# 602 register map
Vendor: bouffalolab; Series: WiFi BT
CPU: 602, little endian
Registers are 32-bit, read-write, reset 0x0 unless marked. A register's access mark holds for its fields unless they carry their own. Offsets are from the block's base; [hi:lo] are bit positions; {n}, {i} and the like mark numbered series.

## rf
Base 0x40001000
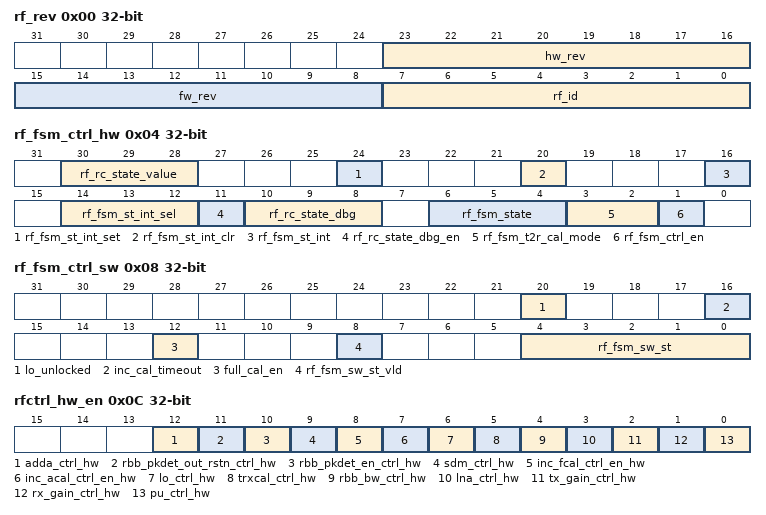
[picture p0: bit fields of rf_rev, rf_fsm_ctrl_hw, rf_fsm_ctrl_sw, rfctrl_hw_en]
0x00 rf_rev — Silicon revision
  [23:16] hw_rev, [15:8] fw_rev, [7:0] rf_id
0x04 rf_fsm_ctrl_hw — Digital Control
  [30:28] rf_rc_state_value, [24] rf_fsm_st_int_set, [20] rf_fsm_st_int_clr, [16] rf_fsm_st_int, [14:12] rf_fsm_st_int_sel, [11] rf_rc_state_dbg_en, [10:8] rf_rc_state_dbg, [6:4] rf_fsm_state, [3:2] rf_fsm_t2r_cal_mode, [1] rf_fsm_ctrl_en
0x08 rf_fsm_ctrl_sw — rfsm status reg
  [20] lo_unlocked, [16] inc_cal_timeout, [12] full_cal_en, [8] rf_fsm_sw_st_vld, [4:0] rf_fsm_sw_st
0x0C rfctrl_hw_en — Control logic switch
  [12] adda_ctrl_hw, [11] rbb_pkdet_out_rstn_ctrl_hw, [10] rbb_pkdet_en_ctrl_hw, [9] sdm_ctrl_hw, [8] inc_fcal_ctrl_en_hw, [7] inc_acal_ctrl_en_hw, [6] lo_ctrl_hw, [5] trxcal_ctrl_hw, [4] rbb_bw_ctrl_hw, [3] lna_ctrl_hw, [2] tx_gain_ctrl_hw, [1] rx_gain_ctrl_hw, [0] pu_ctrl_hw
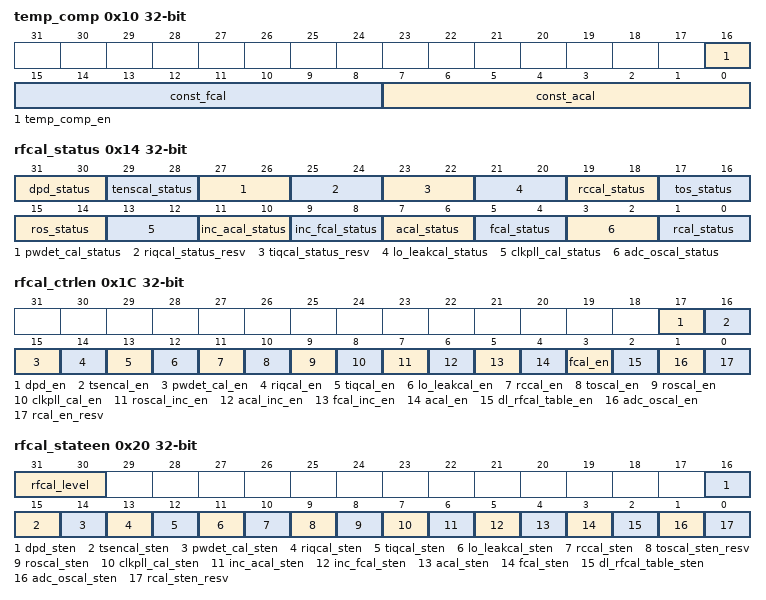
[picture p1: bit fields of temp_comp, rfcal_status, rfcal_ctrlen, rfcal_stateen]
0x10 temp_comp
  [16] temp_comp_en, [15:8] const_fcal, [7:0] const_acal
0x14 rfcal_status
  [31:30] dpd_status, [29:28] tenscal_status, [27:26] pwdet_cal_status, [25:24] riqcal_status_resv, [23:22] tiqcal_status_resv, [21:20] lo_leakcal_status, [19:18] rccal_status, [17:16] tos_status, [15:14] ros_status, [13:12] clkpll_cal_status, [11:10] inc_acal_status, [9:8] inc_fcal_status, [7:6] acal_status, [5:4] fcal_status, [3:2] adc_oscal_status, [1:0] rcal_status
0x18 rfcal_status2
  [1:0] dl_rfcal_table_status
0x1C rfcal_ctrlen — Calibration mode register
  [17] dpd_en, [16] tsencal_en, [15] pwdet_cal_en, [14] riqcal_en, [13] tiqcal_en, [12] lo_leakcal_en, [11] rccal_en, [10] toscal_en, [9] roscal_en, [8] clkpll_cal_en, [7] roscal_inc_en, [6] acal_inc_en, [5] fcal_inc_en, [4] acal_en, [3] fcal_en, [2] dl_rfcal_table_en, [1] adc_oscal_en, [0] rcal_en_resv
0x20 rfcal_stateen — rf calibration state enabl in full cal list
  [31:30] rfcal_level, [16] dpd_sten, [15] tsencal_sten, [14] pwdet_cal_sten, [13] riqcal_sten, [12] tiqcal_sten, [11] lo_leakcal_sten, [10] rccal_sten, [9] toscal_sten_resv, [8] roscal_sten, [7] clkpll_cal_sten, [6] inc_acal_sten, [5] inc_fcal_sten, [4] acal_sten, [3] fcal_sten, [2] dl_rfcal_table_sten, [1] adc_oscal_sten, [0] rcal_sten_resv
0x24 saradc_resv — SARADC Control Registers
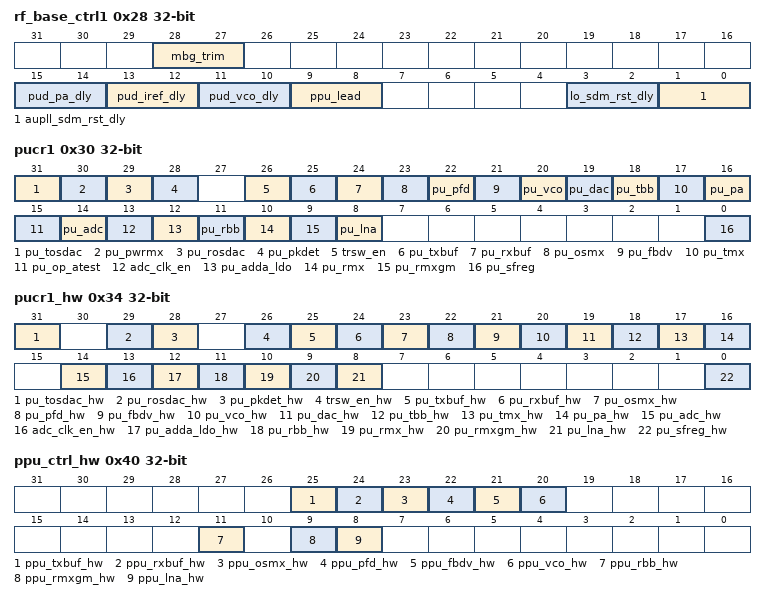
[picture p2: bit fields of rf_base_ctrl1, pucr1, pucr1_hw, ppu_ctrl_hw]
0x28 rf_base_ctrl1 — ZRF Control register 0
  [28:27] mbg_trim, [15:14] pud_pa_dly, [13:12] pud_iref_dly, [11:10] pud_vco_dly, [9:8] ppu_lead, [3:2] lo_sdm_rst_dly, [1:0] aupll_sdm_rst_dly
0x2C rf_base_ctrl2 — ZRF Control register 0
0x30 pucr1
  [31] pu_tosdac, [30] pu_pwrmx, [29] pu_rosdac, [28] pu_pkdet, [26] trsw_en, [25] pu_txbuf, [24] pu_rxbuf, [23] pu_osmx, [22] pu_pfd, [21] pu_fbdv, [20] pu_vco, [19] pu_dac, [18] pu_tbb, [17] pu_tmx, [16] pu_pa, [15] pu_op_atest, [14] pu_adc, [13] adc_clk_en, [12] pu_adda_ldo, [11] pu_rbb, [10] pu_rmx, [9] pu_rmxgm, [8] pu_lna, [0] pu_sfreg
0x34 pucr1_hw — read only from hardware logic
  [31] pu_tosdac_hw, [29] pu_rosdac_hw, [28] pu_pkdet_hw, [26] trsw_en_hw, [25] pu_txbuf_hw, [24] pu_rxbuf_hw, [23] pu_osmx_hw, [22] pu_pfd_hw, [21] pu_fbdv_hw, [20] pu_vco_hw, [19] pu_dac_hw, [18] pu_tbb_hw, [17] pu_tmx_hw, [16] pu_pa_hw, [14] pu_adc_hw, [13] adc_clk_en_hw, [12] pu_adda_ldo_hw, [11] pu_rbb_hw, [10] pu_rmx_hw, [9] pu_rmxgm_hw, [8] pu_lna_hw, [0] pu_sfreg_hw
0x38 pucr2
0x3C pucr2_hw
0x40 ppu_ctrl_hw
  [25] ppu_txbuf_hw, [24] ppu_rxbuf_hw, [23] ppu_osmx_hw, [22] ppu_pfd_hw, [21] ppu_fbdv_hw, [20] ppu_vco_hw, [11] ppu_rbb_hw, [9] ppu_rmxgm_hw, [8] ppu_lna_hw
0x44 pud_ctrl_hw
  [20] pud_vco_hw
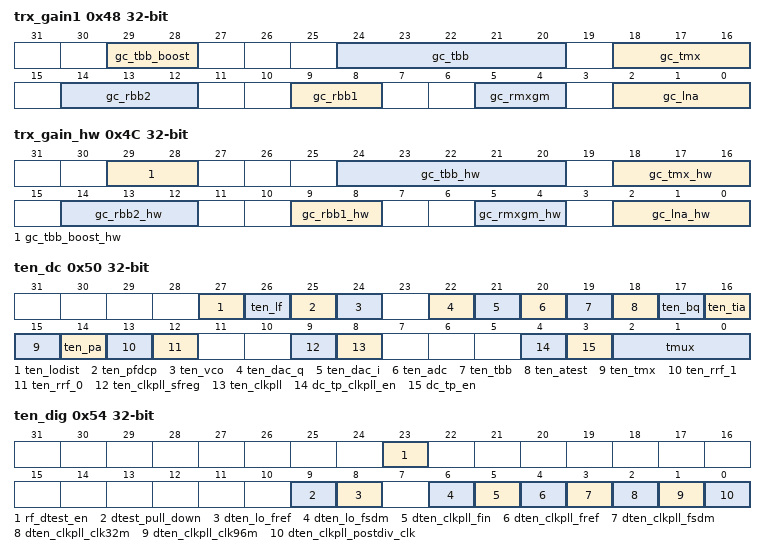
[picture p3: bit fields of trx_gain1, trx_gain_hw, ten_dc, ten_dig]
0x48 trx_gain1 — gain control1
  [29:28] gc_tbb_boost, [24:20] gc_tbb, [18:16] gc_tmx, [14:12] gc_rbb2, [9:8] gc_rbb1, [5:4] gc_rmxgm, [2:0] gc_lna
0x4C trx_gain_hw — trx gain hardware readback
  [29:28] gc_tbb_boost_hw, [24:20] gc_tbb_hw, [18:16] gc_tmx_hw, [14:12] gc_rbb2_hw, [9:8] gc_rbb1_hw, [5:4] gc_rmxgm_hw, [2:0] gc_lna_hw
0x50 ten_dc — dc test register
  [27] ten_lodist, [26] ten_lf, [25] ten_pfdcp, [24] ten_vco, [22] ten_dac_q, [21] ten_dac_i, [20] ten_adc, [19] ten_tbb, [18] ten_atest, [17] ten_bq, [16] ten_tia, [15] ten_tmx, [14] ten_pa, [13] ten_rrf_1, [12] ten_rrf_0, [9] ten_clkpll_sfreg, [8] ten_clkpll, [4] dc_tp_clkpll_en, [3] dc_tp_en, [2:0] tmux
0x54 ten_dig — digital test register
  [23] rf_dtest_en, [9] dtest_pull_down, [8] dten_lo_fref, [6] dten_lo_fsdm, [5] dten_clkpll_fin, [4] dten_clkpll_fref, [3] dten_clkpll_fsdm, [2] dten_clkpll_clk32m, [1] dten_clkpll_clk96m, [0] dten_clkpll_postdiv_clk
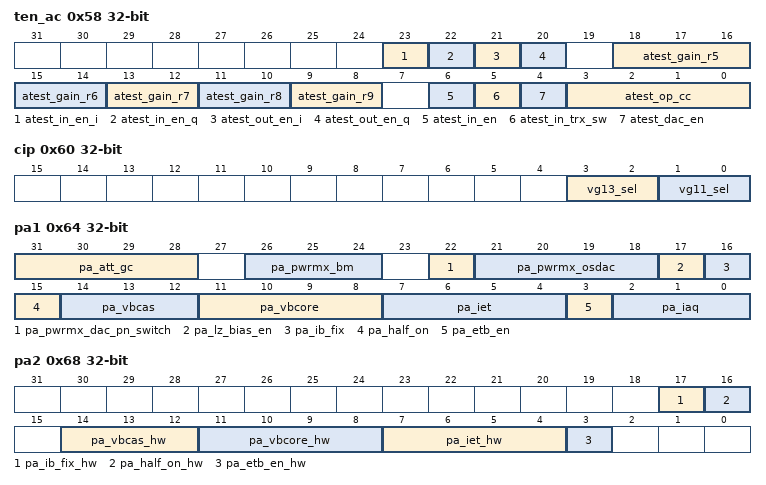
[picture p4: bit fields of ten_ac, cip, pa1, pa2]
0x58 ten_ac — ac test register
  [23] atest_in_en_i, [22] atest_in_en_q, [21] atest_out_en_i, [20] atest_out_en_q, [18:16] atest_gain_r5, [27-2n:26-2n] atest_gain_r{n} (n=6..9), [6] atest_in_en, [5] atest_in_trx_sw, [4] atest_dac_en, [3:0] atest_op_cc
0x5C pmip_mv2aon
0x60 cip — RX normal bias mode registers
  [3:2] vg13_sel, [1:0] vg11_sel
0x64 pa1
  [31:28] pa_att_gc, [26:24] pa_pwrmx_bm, [22] pa_pwrmx_dac_pn_switch, [21:18] pa_pwrmx_osdac, [17] pa_lz_bias_en, [16] pa_ib_fix, [15] pa_half_on, [14:12] pa_vbcas, [11:8] pa_vbcore, [7:4] pa_iet, [3] pa_etb_en, [2:0] pa_iaq
0x68 pa2 — RX normal bias mode registers
  [17] pa_ib_fix_hw, [16] pa_half_on_hw, [14:12] pa_vbcas_hw, [11:8] pa_vbcore_hw, [7:4] pa_iet_hw, [3] pa_etb_en_hw
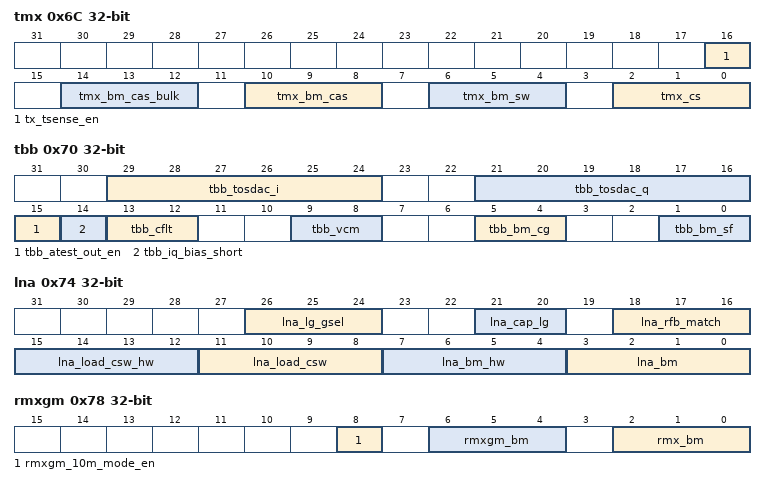
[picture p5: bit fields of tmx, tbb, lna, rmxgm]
0x6C tmx
  [16] tx_tsense_en, [14:12] tmx_bm_cas_bulk, [10:8] tmx_bm_cas, [6:4] tmx_bm_sw, [2:0] tmx_cs
0x70 tbb
  [29:24] tbb_tosdac_i, [21:16] tbb_tosdac_q, [15] tbb_atest_out_en, [14] tbb_iq_bias_short, [13:12] tbb_cflt, [9:8] tbb_vcm, [5:4] tbb_bm_cg, [1:0] tbb_bm_sf
0x74 lna
  [26:24] lna_lg_gsel, [21:20] lna_cap_lg, [18:16] lna_rfb_match, [15:12] lna_load_csw_hw, [11:8] lna_load_csw, [7:4] lna_bm_hw, [3:0] lna_bm
0x78 rmxgm
  [8] rmxgm_10m_mode_en, [6:4] rmxgm_bm, [2:0] rmx_bm
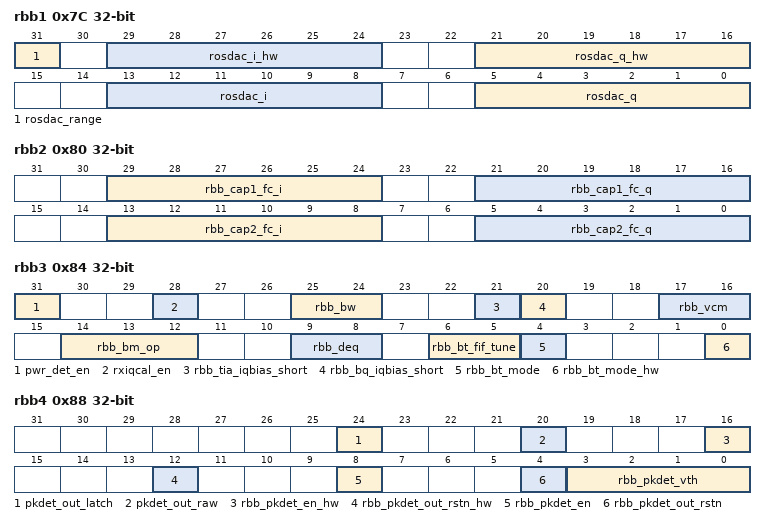
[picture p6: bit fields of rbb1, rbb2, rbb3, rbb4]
0x7C rbb1
  [31] rosdac_range, [29:24] rosdac_i_hw, [21:16] rosdac_q_hw, [13:8] rosdac_i, [5:0] rosdac_q
0x80 rbb2
  [29:24] rbb_cap1_fc_i, [21:16] rbb_cap1_fc_q, [13:8] rbb_cap2_fc_i, [5:0] rbb_cap2_fc_q
0x84 rbb3
  [31] pwr_det_en, [28] rxiqcal_en, [25:24] rbb_bw, [21] rbb_tia_iqbias_short, [20] rbb_bq_iqbias_short, [17:16] rbb_vcm, [14:12] rbb_bm_op, [9:8] rbb_deq, [6:5] rbb_bt_fif_tune, [4] rbb_bt_mode, [0] rbb_bt_mode_hw
0x88 rbb4
  [24] pkdet_out_latch, [20] pkdet_out_raw, [16] rbb_pkdet_en_hw, [12] rbb_pkdet_out_rstn_hw, [8] rbb_pkdet_en, [4] rbb_pkdet_out_rstn, [3:0] rbb_pkdet_vth
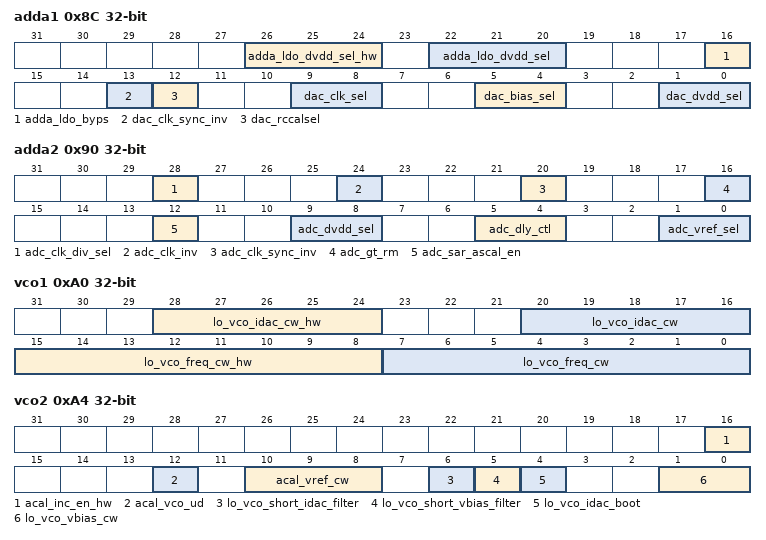
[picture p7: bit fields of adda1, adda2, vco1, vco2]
0x8C adda1
  [26:24] adda_ldo_dvdd_sel_hw, [22:20] adda_ldo_dvdd_sel, [16] adda_ldo_byps, [13] dac_clk_sync_inv, [12] dac_rccalsel, [9:8] dac_clk_sel, [5:4] dac_bias_sel, [1:0] dac_dvdd_sel
0x90 adda2
  [28] adc_clk_div_sel, [24] adc_clk_inv, [20] adc_clk_sync_inv, [16] adc_gt_rm, [12] adc_sar_ascal_en, [9:8] adc_dvdd_sel, [5:4] adc_dly_ctl, [1:0] adc_vref_sel
0xA0 vco1
  [28:24] lo_vco_idac_cw_hw, [20:16] lo_vco_idac_cw, [15:8] lo_vco_freq_cw_hw, [7:0] lo_vco_freq_cw
0xA4 vco2
  [16] acal_inc_en_hw, [12] acal_vco_ud, [10:8] acal_vref_cw, [6] lo_vco_short_idac_filter, [5] lo_vco_short_vbias_filter, [4] lo_vco_idac_boot, [1:0] lo_vco_vbias_cw
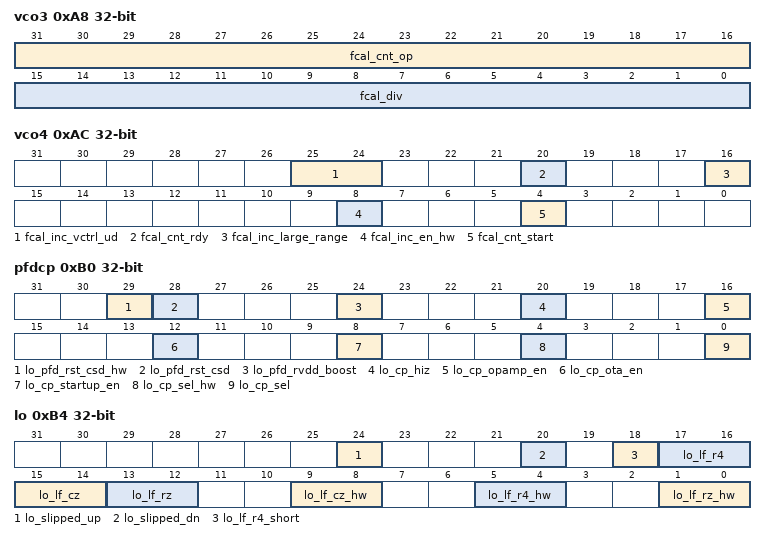
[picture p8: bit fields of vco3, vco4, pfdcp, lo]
0xA8 vco3
  [31:16] fcal_cnt_op, [15:0] fcal_div
0xAC vco4
  [25:24] fcal_inc_vctrl_ud, [20] fcal_cnt_rdy, [16] fcal_inc_large_range, [8] fcal_inc_en_hw, [4] fcal_cnt_start
0xB0 pfdcp
  [29] lo_pfd_rst_csd_hw, [28] lo_pfd_rst_csd, [24] lo_pfd_rvdd_boost, [20] lo_cp_hiz, [16] lo_cp_opamp_en, [12] lo_cp_ota_en, [8] lo_cp_startup_en, [4] lo_cp_sel_hw, [0] lo_cp_sel
0xB4 lo
  [24] lo_slipped_up, [20] lo_slipped_dn, [18] lo_lf_r4_short, [17:16] lo_lf_r4, [15:14] lo_lf_cz, [13:12] lo_lf_rz, [9:8] lo_lf_cz_hw, [5:4] lo_lf_r4_hw, [1:0] lo_lf_rz_hw
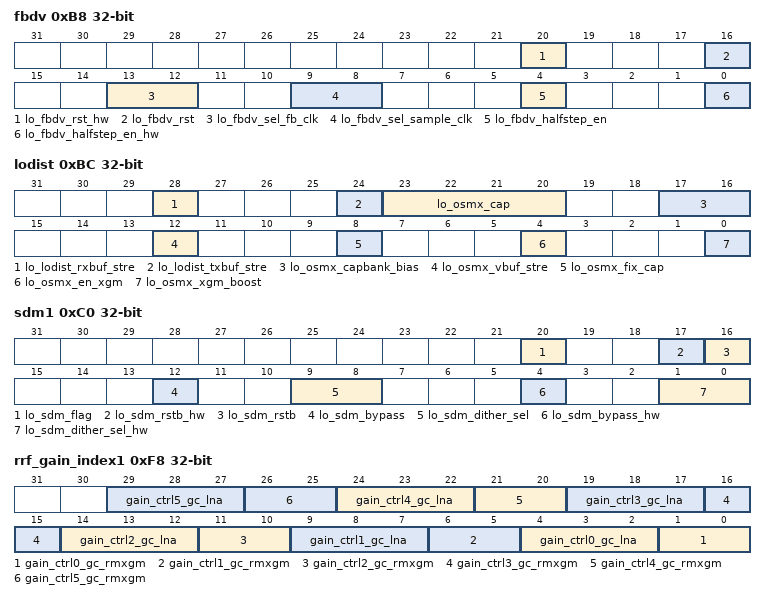
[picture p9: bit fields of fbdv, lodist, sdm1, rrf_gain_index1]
0xB8 fbdv
  [20] lo_fbdv_rst_hw, [16] lo_fbdv_rst, [13:12] lo_fbdv_sel_fb_clk, [9:8] lo_fbdv_sel_sample_clk, [4] lo_fbdv_halfstep_en, [0] lo_fbdv_halfstep_en_hw
0xBC lodist
  [28] lo_lodist_rxbuf_stre, [24] lo_lodist_txbuf_stre, [23:20] lo_osmx_cap, [17:16] lo_osmx_capbank_bias, [12] lo_osmx_vbuf_stre, [8] lo_osmx_fix_cap, [4] lo_osmx_en_xgm, [0] lo_osmx_xgm_boost
0xC0 sdm1
  [20] lo_sdm_flag, [17] lo_sdm_rstb_hw, [16] lo_sdm_rstb, [12] lo_sdm_bypass, [9:8] lo_sdm_dither_sel, [4] lo_sdm_bypass_hw, [1:0] lo_sdm_dither_sel_hw
0xC4 sdm2
  [29:0] lo_sdmin
0xC8 sdm3
  [29:0] lo_sdmin_hw
{0xEC+4i} rf_resv_reg_{i} (i=0..2)
  [31:0] rf_reserved{i}
0xF8 rrf_gain_index1
  [5n+4:5n+2] gain_ctrl{n}_gc_lna (n=0..5), [5n+1:5n] gain_ctrl{n}_gc_rmxgm (n=0..5)
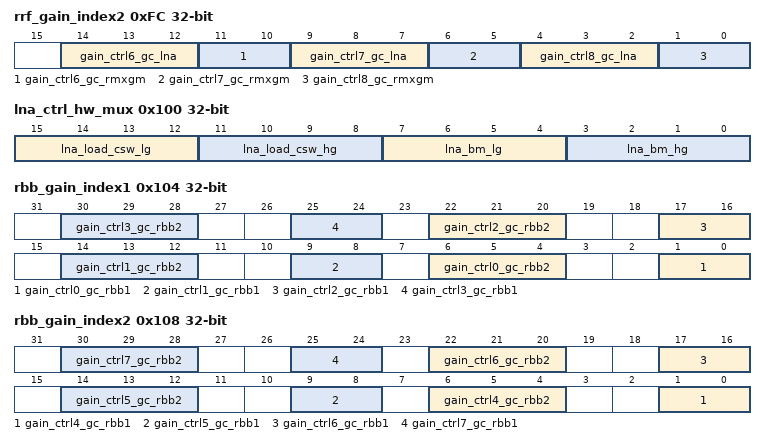
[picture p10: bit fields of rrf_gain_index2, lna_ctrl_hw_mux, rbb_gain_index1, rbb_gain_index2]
0xFC rrf_gain_index2
  [14:12] gain_ctrl6_gc_lna, [11:10] gain_ctrl6_gc_rmxgm, [9:7] gain_ctrl7_gc_lna, [6:5] gain_ctrl7_gc_rmxgm, [4:2] gain_ctrl8_gc_lna, [1:0] gain_ctrl8_gc_rmxgm
0x100 lna_ctrl_hw_mux
  [15:12] lna_load_csw_lg, [11:8] lna_load_csw_hg, [7:4] lna_bm_lg, [3:0] lna_bm_hg
0x104 rbb_gain_index1
  [8n+6:8n+4] gain_ctrl{n}_gc_rbb2 (n=0..3), [8n+1:8n] gain_ctrl{n}_gc_rbb1 (n=0..3)
0x108 rbb_gain_index2
  [8n-26:8n-28] gain_ctrl{n}_gc_rbb2 (n=4..7), [8n-31:8n-32] gain_ctrl{n}_gc_rbb1 (n=4..7)
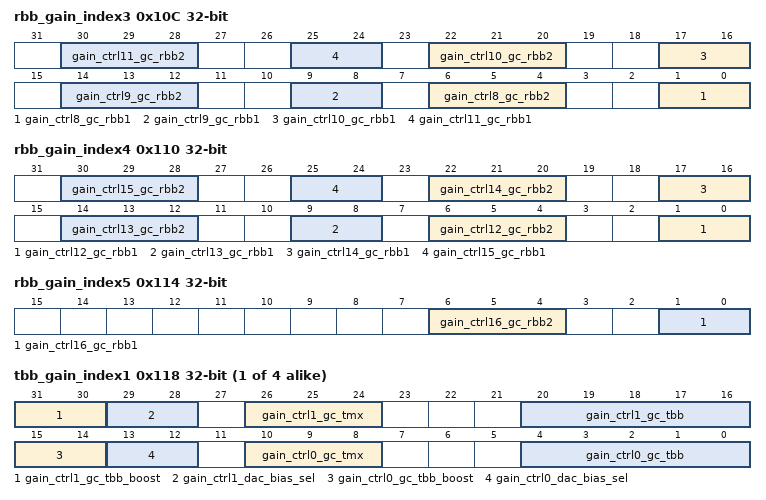
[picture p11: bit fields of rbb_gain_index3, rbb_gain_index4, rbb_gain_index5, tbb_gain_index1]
0x10C rbb_gain_index3
  [8n-58:8n-60] gain_ctrl{n}_gc_rbb2 (n=8..11), [8n-63:8n-64] gain_ctrl{n}_gc_rbb1 (n=8..11)
0x110 rbb_gain_index4
  [8n-90:8n-92] gain_ctrl{n}_gc_rbb2 (n=12..15), [8n-95:8n-96] gain_ctrl{n}_gc_rbb1 (n=12..15)
0x114 rbb_gain_index5
  [6:4] gain_ctrl16_gc_rbb2, [1:0] gain_ctrl16_gc_rbb1
{0x114+4i} tbb_gain_index{i} (i=1..4)
  [31:30] gain_ctrl{2i-1}_gc_tbb_boost, [29:28] gain_ctrl{2i-1}_dac_bias_sel, [26:24] gain_ctrl{2i-1}_gc_tmx, [20:16] gain_ctrl{2i-1}_gc_tbb, [15:14] gain_ctrl{2i-2}_gc_tbb_boost, [13:12] gain_ctrl{2i-2}_dac_bias_sel, [10:8] gain_ctrl{2i-2}_gc_tmx, [4:0] gain_ctrl{2i-2}_gc_tbb
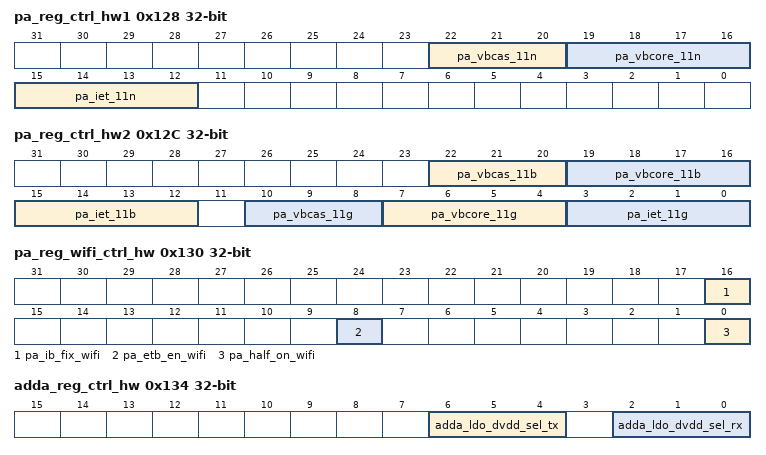
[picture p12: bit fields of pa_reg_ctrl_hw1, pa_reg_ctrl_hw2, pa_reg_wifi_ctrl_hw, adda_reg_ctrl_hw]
0x128 pa_reg_ctrl_hw1
  [22:20] pa_vbcas_11n, [19:16] pa_vbcore_11n, [15:12] pa_iet_11n
0x12C pa_reg_ctrl_hw2
  [22:20] pa_vbcas_11b, [19:16] pa_vbcore_11b, [15:12] pa_iet_11b, [10:8] pa_vbcas_11g, [7:4] pa_vbcore_11g, [3:0] pa_iet_11g
0x130 pa_reg_wifi_ctrl_hw
  [16] pa_ib_fix_wifi, [8] pa_etb_en_wifi, [0] pa_half_on_wifi
0x134 adda_reg_ctrl_hw
  [6:4] adda_ldo_dvdd_sel_tx, [2:0] adda_ldo_dvdd_sel_rx
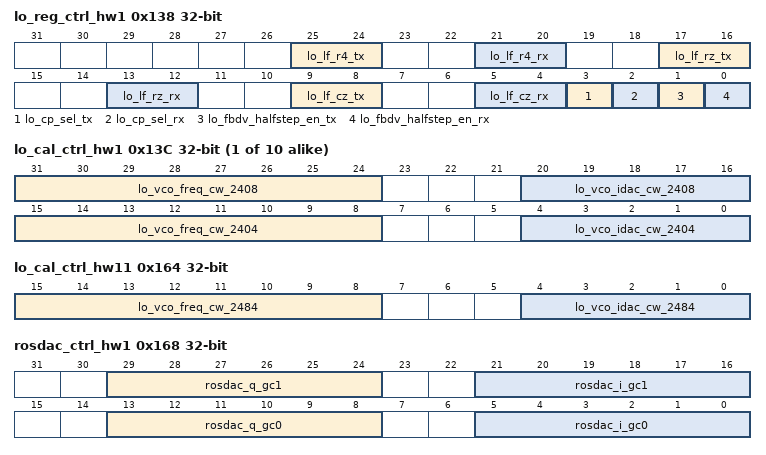
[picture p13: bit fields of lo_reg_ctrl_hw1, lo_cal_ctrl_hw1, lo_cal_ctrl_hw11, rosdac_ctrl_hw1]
0x138 lo_reg_ctrl_hw1
  [25:24] lo_lf_r4_tx, [21:20] lo_lf_r4_rx, [17:16] lo_lf_rz_tx, [13:12] lo_lf_rz_rx, [9:8] lo_lf_cz_tx, [5:4] lo_lf_cz_rx, [3] lo_cp_sel_tx, [2] lo_cp_sel_rx, [1] lo_fbdv_halfstep_en_tx, [0] lo_fbdv_halfstep_en_rx
{0x138+4i} lo_cal_ctrl_hw{i} (i=1..10)
  [31:24] lo_vco_freq_cw_{8i+2400}, [20:16] lo_vco_idac_cw_{8i+2400}, [15:8] lo_vco_freq_cw_{8i+2396}, [4:0] lo_vco_idac_cw_{8i+2396}
0x164 lo_cal_ctrl_hw11
  [15:8] lo_vco_freq_cw_2484, [4:0] lo_vco_idac_cw_2484
0x168 rosdac_ctrl_hw1
  [29:24] rosdac_q_gc1, [21:16] rosdac_i_gc1, [13:8] rosdac_q_gc0, [5:0] rosdac_i_gc0
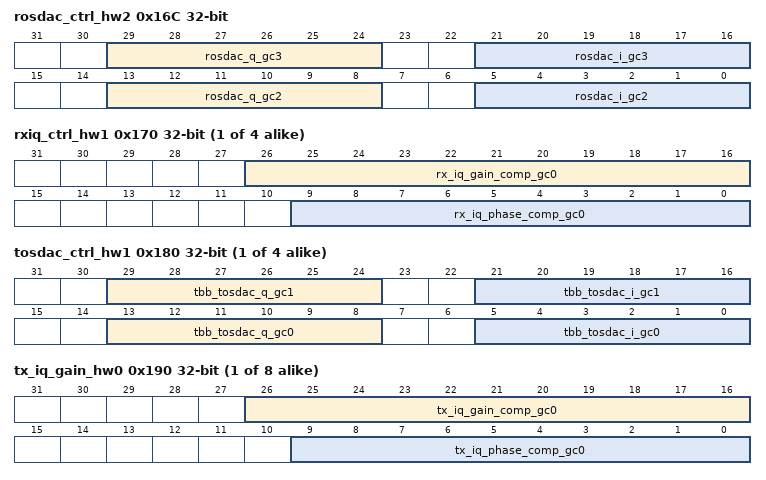
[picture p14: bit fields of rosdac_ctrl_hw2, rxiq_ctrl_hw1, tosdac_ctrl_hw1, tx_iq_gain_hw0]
0x16C rosdac_ctrl_hw2
  [29:24] rosdac_q_gc3, [21:16] rosdac_i_gc3, [13:8] rosdac_q_gc2, [5:0] rosdac_i_gc2
{0x16C+4i} rxiq_ctrl_hw{i} (i=1..4)
  [26:16] rx_iq_gain_comp_gc{i-1}, [9:0] rx_iq_phase_comp_gc{i-1}
{0x17C+4i} tosdac_ctrl_hw{i} (i=1..4)
  [29:24] tbb_tosdac_q_gc{2i-1}, [21:16] tbb_tosdac_i_gc{2i-1}, [13:8] tbb_tosdac_q_gc{2i-2}, [5:0] tbb_tosdac_i_gc{2i-2}
{0x190+4i} tx_iq_gain_hw{i} (i=0..7)
  [26:16] tx_iq_gain_comp_gc{i}, [9:0] tx_iq_phase_comp_gc{i}
0x1B0 lo_sdm_ctrl_hw1
  [27:26] lo_sdm_dither_sel_wlan_2484, [25:24] lo_sdm_dither_sel_wlan_2472, [23:22] lo_sdm_dither_sel_wlan_2467, [21:20] lo_sdm_dither_sel_wlan_2462, [19:18] lo_sdm_dither_sel_wlan_2457, [17:16] lo_sdm_dither_sel_wlan_2452, [15:14] lo_sdm_dither_sel_wlan_2447, [13:12] lo_sdm_dither_sel_wlan_2442, [11:10] lo_sdm_dither_sel_wlan_2437, [9:8] lo_sdm_dither_sel_wlan_2432, [7:6] lo_sdm_dither_sel_wlan_2427, [5:4] lo_sdm_dither_sel_wlan_2422, [3:2] lo_sdm_dither_sel_wlan_2417, [1:0] lo_sdm_dither_sel_wlan_2412
0x1B4 lo_sdm_ctrl_hw2
  [31:30] lo_sdm_dither_sel_ble_2432, [29:28] lo_sdm_dither_sel_ble_2430, [27:26] lo_sdm_dither_sel_ble_2428, [25:24] lo_sdm_dither_sel_ble_2426, [23:22] lo_sdm_dither_sel_ble_2424, [21:20] lo_sdm_dither_sel_ble_2422, [19:18] lo_sdm_dither_sel_ble_2420, [17:16] lo_sdm_dither_sel_ble_2418, [15:14] lo_sdm_dither_sel_ble_2416, [13:12] lo_sdm_dither_sel_ble_2414, [11:10] lo_sdm_dither_sel_ble_2412, [9:8] lo_sdm_dither_sel_ble_2410, [7:6] lo_sdm_dither_sel_ble_2408, [5:4] lo_sdm_dither_sel_ble_2406, [3:2] lo_sdm_dither_sel_ble_2404, [1:0] lo_sdm_dither_sel_ble_2402
0x1B8 lo_sdm_ctrl_hw3
  [31:30] lo_sdm_dither_sel_ble_2464, [29:28] lo_sdm_dither_sel_ble_2462, [27:26] lo_sdm_dither_sel_ble_2460, [25:24] lo_sdm_dither_sel_ble_2458, [23:22] lo_sdm_dither_sel_ble_2456, [21:20] lo_sdm_dither_sel_ble_2454, [19:18] lo_sdm_dither_sel_ble_2452, [17:16] lo_sdm_dither_sel_ble_2450, [15:14] lo_sdm_dither_sel_ble_2448, [13:12] lo_sdm_dither_sel_ble_2446, [11:10] lo_sdm_dither_sel_ble_2444, [9:8] lo_sdm_dither_sel_ble_2442, [7:6] lo_sdm_dither_sel_ble_2440, [5:4] lo_sdm_dither_sel_ble_2438, [3:2] lo_sdm_dither_sel_ble_2436, [1:0] lo_sdm_dither_sel_ble_2434
0x1BC lo_sdm_ctrl_hw4
  [17:16] lo_sdm_dither_sel_ble_tx, [15:14] lo_sdm_dither_sel_ble_2480, [13:12] lo_sdm_dither_sel_ble_2478, [11:10] lo_sdm_dither_sel_ble_2476, [9:8] lo_sdm_dither_sel_ble_2474, [7:6] lo_sdm_dither_sel_ble_2472, [5:4] lo_sdm_dither_sel_ble_2470, [3:2] lo_sdm_dither_sel_ble_2468, [1:0] lo_sdm_dither_sel_ble_2466
0x1C0 lo_sdm_ctrl_hw5
  [17:12] lo_sdm_bypass_mode, [11:0] lo_center_freq_mhz
0x1C4 lo_sdm_ctrl_hw6
  [28:0] lo_sdmin_center
0x1C8 lo_sdm_ctrl_hw7
  [19:0] lo_sdmin_1m
0x1CC lo_sdm_ctrl_hw8
  [19:0] lo_sdmin_if
0x1D0 rbb_bw_ctrl_hw
  [0] rbb_bt_mode_ble
0x20C singen_ctrl0
  [31] singen_en, [30:29] singen_clkdiv_n, [28] singen_unsign_en, [25:16] singen_inc_step0, [9:0] singen_inc_step1
0x210 singen_ctrl1
  [31:28] singen_mode_i, [25:16] singen_clkdiv_i, [15:12] singen_mode_q, [9:0] singen_clkdiv_q
0x214 singen_ctrl2
  [31:22] singen_start_addr0_i, [21:12] singen_start_addr1_i, [10:0] singen_gain_i
0x218 singen_ctrl3
  [31:22] singen_start_addr0_q, [21:12] singen_start_addr1_q, [10:0] singen_gain_q
0x21C singen_ctrl4
  [28] singen_fix_en_i, [27:16] singen_fix_i, [12] singen_fix_en_q, [11:0] singen_fix_q
0x220 rfif_dfe_ctrl0
  [31:28] test_sel, [27] bbmode_4s_en, [26] bbmode_4s, [25] wifimode_4s_en, [24:23] wifimode_4s, [22] rf_ch_ind_ble_4s_en, [21:15] rf_ch_ind_ble_4s, [14] pad_dac_clkout_inv_en, [13] pad_adc_clkout_inv_en, [12:11] tx_test_sel, [10:9] rx_test_sel, [8] tx_dfe_en_4s_en, [7] tx_dfe_en_4s, [6] rx_dfe_en_4s_en, [5] rx_dfe_en_4s, [4] rfckg_dac_afifo_inv, [3] rfckg_adc_clkout_sel, [2] rfckg_adc_afifo_inv, [1] rfckg_txclk_4s_on, [0] rfckg_rxclk_4s_on
0x224 rfif_test_read
  [31:0] test_read
0x228 rfif_dig_ctrl
  [30] rfif_ppud_manaual_en, [29:25] rfif_ppud_cnt1, [24:16] rfif_ppud_cnt2, [3] rfif_int_lo_unlocked_mask, [2] rfckg_rxclk_div2_mode, [1] test_gc_from_pad_en, [0] test_from_pad_en
{0x22C+4i} rf_data_temp_{i} (i=0..3)
0x23C rf_sram_ctrl0
  [19] rf_sram_ext_clr, [18] rf_sram_swap, [17:16] rf_sram_link_mode, [15:0] rf_sram_link_dly
0x240 rf_sram_ctrl1
  [31:16] rf_sram_adc_done_cnt, [3] rf_sram_adc_sts_clr, [2] rf_sram_adc_loop_en, [1] rf_sram_adc_en, [0] rf_sram_adc_done
0x244 rf_sram_ctrl2
  [31:16] rf_sram_adc_addr_start, [15:0] rf_sram_adc_addr_end
0x248 rf_sram_ctrl3
  [31:0] rf_sram_adc_sts
0x24C rf_sram_ctrl4
  [31:16] rf_sram_dac_done_cnt, [3] rf_sram_dac_sts_clr, [2] rf_sram_dac_loop_en, [1] rf_sram_dac_en, [0] rf_sram_dac_done
0x250 rf_sram_ctrl5
  [31:16] rf_sram_dac_addr_start, [15:0] rf_sram_dac_addr_end
0x254 rf_sram_ctrl6
  [31:0] rf_sram_dac_sts
0x258 rf_ical_ctrl0
  [31] rf_ical_f_ud_inv_en, [30] rf_ical_a_ud_inv_en, [29:20] rf_ical_f_cnt_n, [19:10] rf_ical_a_cnt_n, [9:0] rf_ical_r_cnt_n
0x25C rf_ical_ctrl1
  [29:20] rf_ical_r_os_i, [19:10] rf_ical_r_os_q, [4:0] rf_ical_r_avg_n
0x260 rf_ical_ctrl2
  [15:0] rf_ical_period_n
0x264 rf_fsm_ctrl0
  [11:0] rf_ch_ind_wifi
0x268 rf_fsm_ctrl1
  [29:20] rf_fsm_pu_pa_dly_n, [19] rf_fsm_lo_rdy_sbclr, [18] rf_fsm_lo_rdy_4s_1, [17] rf_fsm_lo_rdy_rst, [16] rf_fsm_lo_rdy, [15:0] rf_fsm_lo_time
0x26C rf_fsm_ctrl2
  [29:20] rf_fsm_dfe_rx_dly_n, [19:10] rf_fsm_dfe_tx_dly_n, [6] rf_trx_ble_4s_en, [5] rf_trx_sw_ble_4s, [4] rf_trx_en_ble_4s, [3] rf_fsm_st_dbg_en, [2:0] rf_fsm_st_dbg
0x270 rf_pkdet_ctrl0
  [5] pkdet_out_mode, [4] pkdet_out_cnt_en, [3:0] pkdet_out_cnt_sts
0x600 dfe_ctrl_0
  [31] tx_dvga_gain_ctrl_hw, [30:24] tx_dvga_gain_qdb, [23] tx_iqc_gain_en, [22:12] tx_iqc_gain, [10] tx_iqc_phase_en, [9:0] tx_iqc_phase
0x604 dfe_ctrl_1
  [31] tx_dac_iq_swap, [30] tx_dac_dat_format, [27:16] tx_dac_os_q, [11:0] tx_dac_os_i
0x608 dfe_ctrl_2
  [31] rx_adc_iq_swap, [30] rx_adc_dat_format, [29] rx_adc_low_pow_en, [28] rx_adc_dce_flt_en, [25:16] rx_adc_os_q, [9:0] rx_adc_os_i
0x60C dfe_ctrl_3
  [26] rx_adc_4s_q_en, [25:16] rx_adc_4s_q_val, [10] rx_adc_4s_i_en, [9:0] rx_adc_4s_i_val
0x610 dfe_ctrl_4
  [31] rx_pf_i_en, [30] rx_pf_q_en, [25:16] rx_pf_th1, [9:0] rx_pf_th2
0x614 dfe_ctrl_5
  [23] rx_iqc_gain_en, [22:12] rx_iqc_gain, [10] rx_iqc_phase_en, [9:0] rx_iqc_phase
0x618 dfe_ctrl_6
  [31:30] rx_pm_in_sel, [29] rx_pm_en, [28] rx_pm_done, [20] rx_pm_freqshift_en, [19:0] rx_pm_freqshift_cw
0x61C dfe_ctrl_7
  [31:16] rx_pm_acc_len, [15:0] rx_pm_start_ofs
0x620 dfe_ctrl_8
  [24:0] rx_pm_iqacc_i
0x624 dfe_ctrl_9
  [24:0] rx_pm_iqacc_q
0x628 dfe_ctrl_10
  [26:16] dfe_dac_raw_q, [10:0] dfe_dac_raw_i
0x62C dfe_ctrl_11
  [25:16] dfe_adc_raw_q, [9:0] dfe_adc_raw_i
0x630 dfe_ctrl_12
  [8n+6:8n] tx_dvga_gain_qdb_gc{n} (n=0..3)
0x634 dfe_ctrl_13
  [8n-26:8n-32] tx_dvga_gain_qdb_gc{n} (n=4..7)
0x638 dfe_ctrl_14
  [8n-58:8n-64] tx_dvga_gain_qdb_gc{n} (n=8..11)
0x63C dfe_ctrl_15
  [8n-90:8n-96] tx_dvga_gain_qdb_gc{n} (n=12..15)
0x640 dfe_ctrl_16
  [4n+2:4n] rf_tbb_ind_gc{n} (n=0..7)
0x644 dfe_ctrl_17
  [4n-30:4n-32] rf_tbb_ind_gc{n} (n=8..15)
0x648 dfe_ctrl_18
  [22:16] tx_dvga_gain_qdb_ble_gc2, [14:8] tx_dvga_gain_qdb_ble_gc1, [6:0] tx_dvga_gain_qdb_ble_gc0
